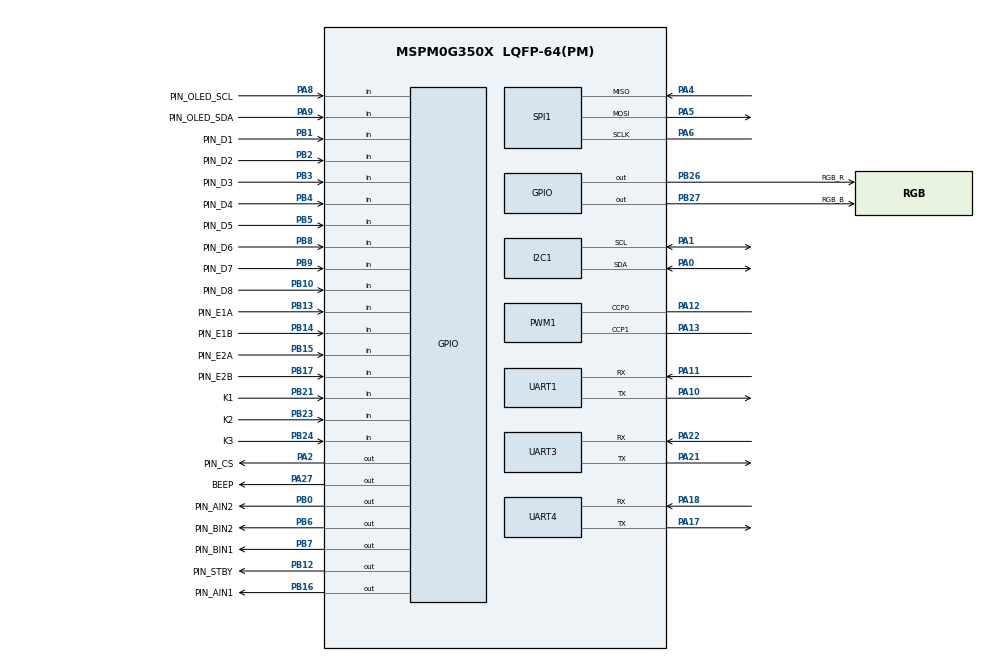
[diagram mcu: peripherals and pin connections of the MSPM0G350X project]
/**
 * @cliArgs --device "MSPM0G350X" --part "Default" --package "LQFP-64(PM)" --product "mspm0_sdk@2.11.00.07"
 * @versions {"tool":"1.26.2+4477"}
 */

/**
 * Import the modules used in this configuration.
 */
const ADC12  = scripting.addModule("/ti/driverlib/ADC12", {}, false);
const ADC121 = ADC12.addInstance();
const GPIO   = scripting.addModule("/ti/driverlib/GPIO", {}, false);
const GPIO1  = GPIO.addInstance();
const GPIO2  = GPIO.addInstance();
const GPIO3  = GPIO.addInstance();
const GPIO4  = GPIO.addInstance();
const GPIO5  = GPIO.addInstance();
const GPIO6  = GPIO.addInstance();
const GPIO7  = GPIO.addInstance();
const GPIO8  = GPIO.addInstance();
const GPIO9  = GPIO.addInstance();
const I2C    = scripting.addModule("/ti/driverlib/I2C", {}, false);
const I2C1   = I2C.addInstance();
const PWM    = scripting.addModule("/ti/driverlib/PWM", {}, false);
const PWM1   = PWM.addInstance();
const SPI    = scripting.addModule("/ti/driverlib/SPI", {}, false);
const SPI1   = SPI.addInstance();
const SYSCTL = scripting.addModule("/ti/driverlib/SYSCTL");
const TIMER  = scripting.addModule("/ti/driverlib/TIMER", {}, false);
const TIMER1 = TIMER.addInstance();
const TIMER2 = TIMER.addInstance();
const TIMER3 = TIMER.addInstance();
const UART   = scripting.addModule("/ti/driverlib/UART", {}, false);
const UART1  = UART.addInstance();
const UART2  = UART.addInstance();
const UART3  = UART.addInstance();
const UART4  = UART.addInstance();

/**
 * Write custom configuration values to the imported modules.
 */
const divider7       = system.clockTree["PLL_PDIV"];
divider7.divideValue = 8;

const divider9       = system.clockTree["UDIV"];
divider9.divideValue = 2;

const gate7  = system.clockTree["MFCLKGATE"];
gate7.enable = true;

const multiplier2         = system.clockTree["PLL_QDIV"];
multiplier2.multiplyValue = 40;

const mux8       = system.clockTree["HSCLKMUX"];
mux8.inputSelect = "HSCLKMUX_SYSPLL0";

ADC121.$name                             = "ADC12_0";
ADC121.sampClkSrc                        = "DL_ADC12_CLOCK_ULPCLK";
ADC121.sampClkDiv                        = "DL_ADC12_CLOCK_DIVIDE_8";
ADC121.repeatMode                        = true;
ADC121.sampleTime0                       = "2 us";
ADC121.adcMem0_name                      = "ADC_CH0";
ADC121.configureDMA                      = true;
ADC121.sampCnt                           = 1;
ADC121.enabledDMATriggers                = ["DL_ADC12_DMA_MEM0_RESULT_LOADED"];
ADC121.peripheral.$assign                = "ADC1";
ADC121.peripheral.adcPin0.$assign        = "PA15";
ADC121.adcPin0Config.$name               = "ti_driverlib_gpio_GPIOPinGeneric9";
ADC121.DMA_CHANNEL.$name                 = "DMA_CH0";
ADC121.DMA_CHANNEL.srcLength             = "HALF_WORD";
ADC121.DMA_CHANNEL.dstLength             = "HALF_WORD";
ADC121.DMA_CHANNEL.addressMode           = "f2b";
ADC121.DMA_CHANNEL.configureTransferSize = true;
ADC121.DMA_CHANNEL.transferSize          = 40;
ADC121.DMA_CHANNEL.transferMode          = "FULL_CH_REPEAT_SINGLE";

const Board = scripting.addModule("/ti/driverlib/Board", {}, false);

GPIO1.$name                         = "GPIO_IN";
GPIO1.port                          = "PORTB";
GPIO1.associatedPins.create(4);
GPIO1.associatedPins[0].$name       = "PIN_AIN1";
GPIO1.associatedPins[0].pin.$assign = "PB16";
GPIO1.associatedPins[1].$name       = "PIN_AIN2";
GPIO1.associatedPins[1].pin.$assign = "PB0";
GPIO1.associatedPins[2].$name       = "PIN_BIN1";
GPIO1.associatedPins[2].pin.$assign = "PB7";
GPIO1.associatedPins[3].$name       = "PIN_BIN2";
GPIO1.associatedPins[3].pin.$assign = "PB6";

GPIO2.$name                         = "GPIO_STBY";
GPIO2.port                          = "PORTB";
GPIO2.associatedPins[0].$name       = "PIN_STBY";
GPIO2.associatedPins[0].pin.$assign = "PB12";

GPIO3.$name                         = "GPIO_TRACK";
GPIO3.port                          = "PORTB";
GPIO3.associatedPins.create(8);
GPIO3.associatedPins[0].$name       = "PIN_D1";
GPIO3.associatedPins[0].direction   = "INPUT";
GPIO3.associatedPins[0].pin.$assign = "PB1";
GPIO3.associatedPins[1].$name       = "PIN_D2";
GPIO3.associatedPins[1].direction   = "INPUT";
GPIO3.associatedPins[1].pin.$assign = "PB2";
GPIO3.associatedPins[2].$name       = "PIN_D3";
GPIO3.associatedPins[2].direction   = "INPUT";
GPIO3.associatedPins[2].pin.$assign = "PB3";
GPIO3.associatedPins[3].$name       = "PIN_D4";
GPIO3.associatedPins[3].direction   = "INPUT";
GPIO3.associatedPins[3].pin.$assign = "PB4";
GPIO3.associatedPins[4].$name       = "PIN_D5";
GPIO3.associatedPins[4].direction   = "INPUT";
GPIO3.associatedPins[4].pin.$assign = "PB5";
GPIO3.associatedPins[5].$name       = "PIN_D6";
GPIO3.associatedPins[5].direction   = "INPUT";
GPIO3.associatedPins[5].pin.$assign = "PB8";
GPIO3.associatedPins[6].$name       = "PIN_D7";
GPIO3.associatedPins[6].direction   = "INPUT";
GPIO3.associatedPins[6].pin.$assign = "PB9";
GPIO3.associatedPins[7].$name       = "PIN_D8";
GPIO3.associatedPins[7].direction   = "INPUT";
GPIO3.associatedPins[7].pin.$assign = "PB10";

GPIO4.$name                              = "GPIO_ENCODER";
GPIO4.port                               = "PORTB";
GPIO4.associatedPins.create(4);
GPIO4.associatedPins[0].$name            = "PIN_E1A";
GPIO4.associatedPins[0].direction        = "INPUT";
GPIO4.associatedPins[0].internalResistor = "PULL_UP";
GPIO4.associatedPins[0].interruptEn      = true;
GPIO4.associatedPins[0].polarity         = "RISE";
GPIO4.associatedPins[0].pin.$assign      = "PB13";
GPIO4.associatedPins[1].$name            = "PIN_E1B";
GPIO4.associatedPins[1].direction        = "INPUT";
GPIO4.associatedPins[1].internalResistor = "PULL_UP";
GPIO4.associatedPins[1].interruptEn      = true;
GPIO4.associatedPins[1].polarity         = "RISE";
GPIO4.associatedPins[1].pin.$assign      = "PB14";
GPIO4.associatedPins[2].$name            = "PIN_E2A";
GPIO4.associatedPins[2].direction        = "INPUT";
GPIO4.associatedPins[2].internalResistor = "PULL_UP";
GPIO4.associatedPins[2].interruptEn      = true;
GPIO4.associatedPins[2].polarity         = "RISE";
GPIO4.associatedPins[2].pin.$assign      = "PB15";
GPIO4.associatedPins[3].$name            = "PIN_E2B";
GPIO4.associatedPins[3].direction        = "INPUT";
GPIO4.associatedPins[3].internalResistor = "PULL_UP";
GPIO4.associatedPins[3].interruptEn      = true;
GPIO4.associatedPins[3].polarity         = "RISE";
GPIO4.associatedPins[3].pin.$assign      = "PB17";

GPIO5.$name                              = "GPIO_OLED";
GPIO5.port                               = "PORTA";
GPIO5.associatedPins.create(2);
GPIO5.associatedPins[0].$name            = "PIN_OLED_SCL";
GPIO5.associatedPins[0].direction        = "INPUT";
GPIO5.associatedPins[0].internalResistor = "PULL_UP";
GPIO5.associatedPins[0].pin.$assign      = "PA8";
GPIO5.associatedPins[1].$name            = "PIN_OLED_SDA";
GPIO5.associatedPins[1].direction        = "INPUT";
GPIO5.associatedPins[1].internalResistor = "PULL_UP";
GPIO5.associatedPins[1].pin.$assign      = "PA9";

GPIO6.$name                         = "GPIO_LEDS";
GPIO6.associatedPins.create(2);
GPIO6.associatedPins[0].$name       = "RGB_R";
GPIO6.associatedPins[0].pin.$assign = "PB26";
GPIO6.associatedPins[1].$name       = "RGB_B";
GPIO6.associatedPins[1].pin.$assign = "PB27";

GPIO7.$name                         = "GPIO_BEEP";
GPIO7.associatedPins[0].$name       = "BEEP";
GPIO7.associatedPins[0].pin.$assign = "PA27";

GPIO8.$name                              = "GPIO_KEY";
GPIO8.associatedPins.create(3);
GPIO8.associatedPins[0].$name            = "K1";
GPIO8.associatedPins[0].direction        = "INPUT";
GPIO8.associatedPins[0].internalResistor = "PULL_UP";
GPIO8.associatedPins[0].pin.$assign      = "PB21";
GPIO8.associatedPins[1].$name            = "K2";
GPIO8.associatedPins[1].direction        = "INPUT";
GPIO8.associatedPins[1].internalResistor = "PULL_UP";
GPIO8.associatedPins[1].pin.$assign      = "PB23";
GPIO8.associatedPins[2].$name            = "K3";
GPIO8.associatedPins[2].direction        = "INPUT";
GPIO8.associatedPins[2].internalResistor = "PULL_UP";
GPIO8.associatedPins[2].pin.$assign      = "PB24";

GPIO9.$name                          = "GPIO_ICM_SPI_CS";
GPIO9.port                           = "PORTA";
GPIO9.associatedPins[0].$name        = "PIN_CS";
GPIO9.associatedPins[0].initialValue = "SET";
GPIO9.associatedPins[0].pin.$assign  = "PA2";

I2C1.$name                     = "I2C_0";
I2C1.basicEnableController     = true;
I2C1.advControllerTXFIFOTRIG   = "BYTES_1";
I2C1.peripheral.$assign        = "I2C0";
I2C1.peripheral.sdaPin.$assign = "PA0";
I2C1.peripheral.sclPin.$assign = "PA1";
I2C1.sdaPinConfig.$name        = "ti_driverlib_gpio_GPIOPinGeneric2";
I2C1.sclPinConfig.$name        = "ti_driverlib_gpio_GPIOPinGeneric3";

PWM1.$name                      = "PWM_0";
PWM1.timerCount                 = 2500;
PWM1.peripheral.$assign         = "TIMG0";
PWM1.peripheral.ccp0Pin.$assign = "PA12";
PWM1.peripheral.ccp1Pin.$assign = "PA13";
PWM1.PWM_CHANNEL_0.$name        = "ti_driverlib_pwm_PWMTimerCC0";
PWM1.PWM_CHANNEL_1.$name        = "ti_driverlib_pwm_PWMTimerCC1";
PWM1.ccp0PinConfig.$name        = "ti_driverlib_gpio_GPIOPinGeneric0";
PWM1.ccp1PinConfig.$name        = "ti_driverlib_gpio_GPIOPinGeneric1";

SPI1.$name                              = "SPI_ICM";
SPI1.frameFormat                        = "MOTO3";
SPI1.polarity                           = "1";
SPI1.phase                              = "1";
SPI1.targetBitRate                      = 2000000;
SPI1.chipSelect                         = [];
SPI1.sclkPinConfig.direction            = scripting.forceWrite("OUTPUT");
SPI1.sclkPinConfig.onlyInternalResistor = scripting.forceWrite(false);
SPI1.sclkPinConfig.passedPeripheralType = scripting.forceWrite("Digital");
SPI1.sclkPinConfig.$name                = "ti_driverlib_gpio_GPIOPinGeneric6";
SPI1.mosiPinConfig.direction            = scripting.forceWrite("OUTPUT");
SPI1.mosiPinConfig.hideOutputInversion  = scripting.forceWrite(false);
SPI1.mosiPinConfig.onlyInternalResistor = scripting.forceWrite(false);
SPI1.mosiPinConfig.passedPeripheralType = scripting.forceWrite("Digital");
SPI1.mosiPinConfig.$name                = "ti_driverlib_gpio_GPIOPinGeneric7";
SPI1.misoPinConfig.onlyInternalResistor = scripting.forceWrite(false);
SPI1.misoPinConfig.passedPeripheralType = scripting.forceWrite("Digital");
SPI1.misoPinConfig.$name                = "ti_driverlib_gpio_GPIOPinGeneric8";
SPI1.peripheral.$assign                 = "SPI0";
SPI1.peripheral.sclkPin.$assign         = "PA6";
SPI1.peripheral.mosiPin.$assign         = "PA5";
SPI1.peripheral.misoPin.$assign         = "PA4";

SYSCTL.forceDefaultClkConfig = true;
SYSCTL.clockTreeEn           = true;

TIMER1.$name              = "TIMER_0";
TIMER1.timerPeriod        = "20 ms";
TIMER1.timerStartTimer    = true;
TIMER1.interrupts         = ["ZERO"];
TIMER1.timerMode          = "PERIODIC";
TIMER1.timerClkDiv        = 8;
TIMER1.timerClkPrescale   = 100;
TIMER1.peripheral.$assign = "TIMG6";

TIMER2.$name              = "TIMER_ENCODER";
TIMER2.timerPeriod        = "50 ms";
TIMER2.interrupts         = ["ZERO"];
TIMER2.timerMode          = "PERIODIC";
TIMER2.timerClkDiv        = 8;
TIMER2.timerClkPrescale   = 100;
TIMER2.peripheral.$assign = "TIMG7";

TIMER3.$name              = "TIMER_SOUND_LIGHT";
TIMER3.timerPeriod        = "20 ms";
TIMER3.interrupts         = ["ZERO"];
TIMER3.timerMode          = "PERIODIC";
TIMER3.timerClkDiv        = 8;
TIMER3.timerClkPrescale   = 100;
TIMER3.peripheral.$assign = "TIMG8";

UART1.$name                    = "UART_0";
UART1.targetBaudRate           = 115200;
UART1.uartClkSrc               = "MFCLK";
UART1.enabledInterrupts        = ["RX"];
UART1.peripheral.$assign       = "UART0";
UART1.peripheral.rxPin.$assign = "PA11";
UART1.peripheral.txPin.$assign = "PA10";
UART1.txPinConfig.$name        = "ti_driverlib_gpio_GPIOPinGeneric4";
UART1.rxPinConfig.$name        = "ti_driverlib_gpio_GPIOPinGeneric5";

UART2.$name             = "UART_1";
UART2.targetBaudRate    = 115200;
UART2.txPinConfig.$name = "ti_driverlib_gpio_GPIOPinGeneric10";
UART2.rxPinConfig.$name = "ti_driverlib_gpio_GPIOPinGeneric11";

UART3.$name                    = "UART_2";
UART3.targetBaudRate           = 115200;
UART3.enabledInterrupts        = ["RX"];
UART3.peripheral.$assign       = "UART2";
UART3.peripheral.rxPin.$assign = "PA22";
UART3.peripheral.txPin.$assign = "PA21";
UART3.txPinConfig.$name        = "ti_driverlib_gpio_GPIOPinGeneric12";
UART3.rxPinConfig.$name        = "ti_driverlib_gpio_GPIOPinGeneric13";

UART4.$name                    = "UART_3";
UART4.targetBaudRate           = 115200;
UART4.peripheral.$assign       = "UART1";
UART4.peripheral.rxPin.$assign = "PA18";
UART4.peripheral.txPin.$assign = "PA17";
UART4.txPinConfig.$name        = "ti_driverlib_gpio_GPIOPinGeneric14";
UART4.rxPinConfig.$name        = "ti_driverlib_gpio_GPIOPinGeneric15";

/**
 * Pinmux solution for unlocked pins/peripherals. This ensures that minor changes to the automatic solver in a future
 * version of the tool will not impact the pinmux you originally saw.  These lines can be completely deleted in order to
 * re-solve from scratch.
 */
ADC121.DMA_CHANNEL.peripheral.$suggestSolution = "DMA_CH0";
Board.peripheral.$suggestSolution              = "DEBUGSS";
Board.peripheral.swclkPin.$suggestSolution     = "PA20";
Board.peripheral.swdioPin.$suggestSolution     = "PA19";
UART2.peripheral.$suggestSolution              = "UART3";
UART2.peripheral.rxPin.$suggestSolution        = "PA25";
UART2.peripheral.txPin.$suggestSolution        = "PA14";
